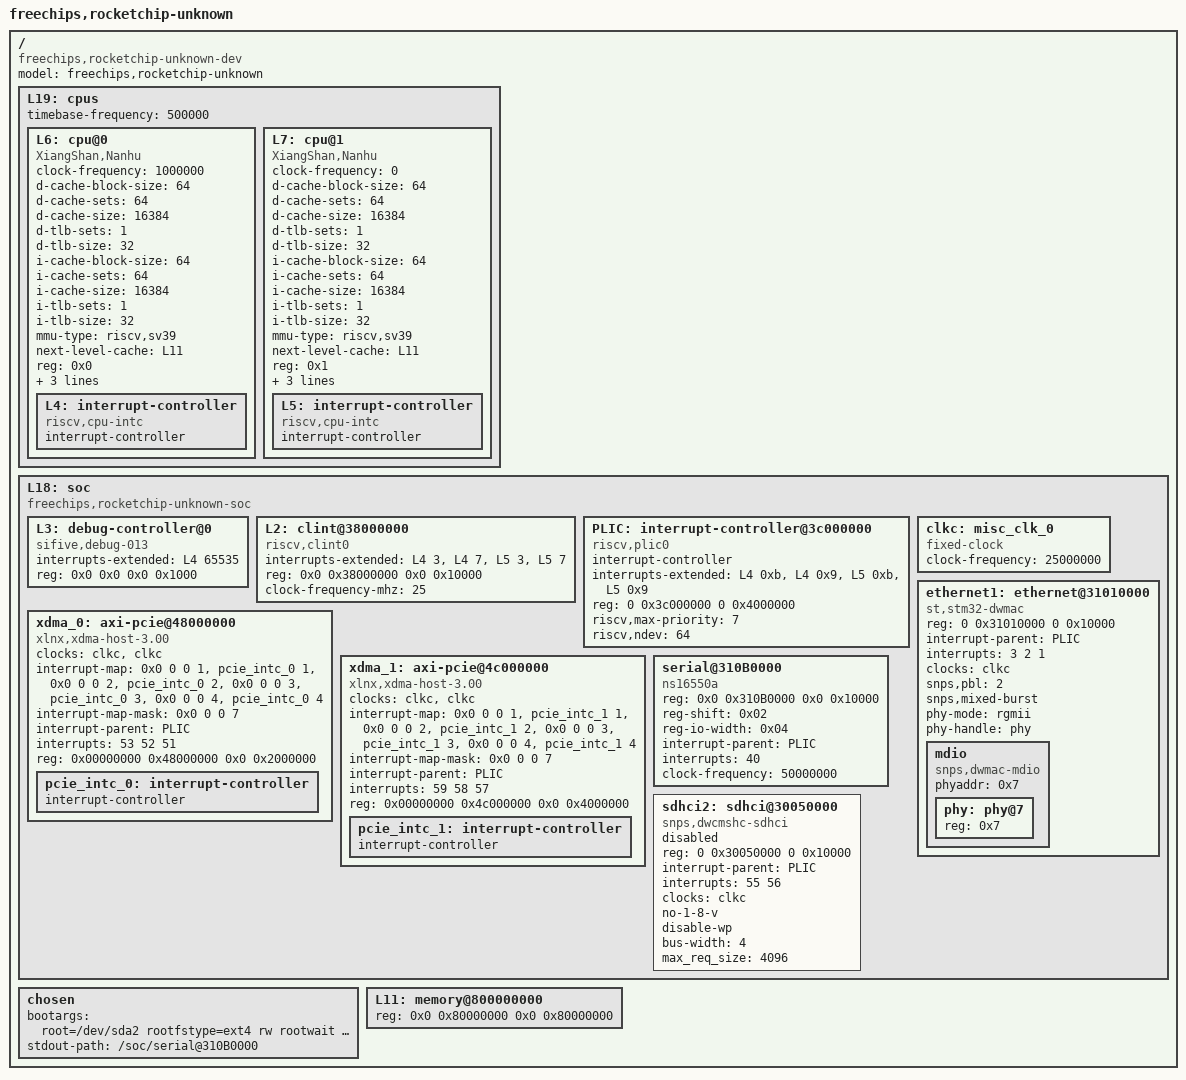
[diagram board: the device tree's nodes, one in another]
/dts-v1/;

/ {
	#address-cells = <2>;
	#size-cells = <2>;
	compatible = "freechips,rocketchip-unknown-dev";
	model = "freechips,rocketchip-unknown";
	L19: cpus {
		#address-cells = <1>;
		#size-cells = <0>;
    	timebase-frequency = <500000>;//500Khz
		L6: cpu@0 {
			clock-frequency = <1000000>;
			compatible = "XiangShan,Nanhu", "riscv";
			d-cache-block-size = <64>;
			d-cache-sets = <64>;
			d-cache-size = <16384>;
			d-tlb-sets = <1>;
			d-tlb-size = <32>;
			device_type = "cpu";
			i-cache-block-size = <64>;
			i-cache-sets = <64>;
			i-cache-size = <16384>;
			i-tlb-sets = <1>;
			i-tlb-size = <32>;
			mmu-type = "riscv,sv39";
			next-level-cache = <&L11>;
			reg = <0x0>;
			riscv,isa = "rv64imafdc";
			status = "okay";
			timebase-frequency = <500000>;//500Khz
			tlb-split;
			L4: interrupt-controller {
				#interrupt-cells = <1>;
				compatible = "riscv,cpu-intc";
				interrupt-controller;
			};
		};
        L7: cpu@1 {
			clock-frequency = <0>;
			compatible = "XiangShan,Nanhu", "riscv";
			d-cache-block-size = <64>;
			d-cache-sets = <64>;
			d-cache-size = <16384>;
			d-tlb-sets = <1>;
			d-tlb-size = <32>;
			device_type = "cpu";
			i-cache-block-size = <64>;
			i-cache-sets = <64>;
			i-cache-size = <16384>;
			i-tlb-sets = <1>;
			i-tlb-size = <32>;
			mmu-type = "riscv,sv39";
			next-level-cache = <&L11>;
			reg = <0x1>;
			riscv,isa = "rv64imafdc";
			status = "okay";
			timebase-frequency = <500000>;//500Khz
			tlb-split;
			L5: interrupt-controller {
				#interrupt-cells = <1>;
				compatible = "riscv,cpu-intc";
				interrupt-controller;
			};
		};

	};
	L18: soc {
		#address-cells = <2>;
		#size-cells = <2>;
		compatible = "freechips,rocketchip-unknown-soc", "simple-bus";
		ranges;
		L3: debug-controller@0 {
			compatible = "sifive,debug-013", "riscv,debug-013";
			interrupts-extended = <&L4 65535>;
			reg = <0x0 0x0 0x0 0x1000>;
			reg-names = "control";
		};

        L2: clint@38000000 {
            compatible = "riscv,clint0";
            interrupts-extended = <&L4 3 &L4 7 &L5 3 &L5 7>;
            reg = <0x0 0x38000000 0x0 0x10000>;
            reg-names = "control";
            clock-frequency-mhz = <25>;
        };

        PLIC: interrupt-controller@3c000000 {
            #interrupt-cells = <1>;
            compatible = "riscv,plic0";
            interrupt-controller;
            //interrupts-extended = <&L4 9 &L4 11 &L5 9 &L5 11>;
            interrupts-extended = <&L4 0xb &L4 0x9 &L5 0xb &L5 0x9>;
            //reg = <0 0xc000000 0 0x4000000>;
            reg = <0 0x3c000000 0 0x4000000>;
            reg-names = "control";
            riscv,max-priority = <7>;
            riscv,ndev = <64>;
        };

        clkc: misc_clk_0 {
            #clock-cells = <0>;
            clock-frequency = <25000000>;
            compatible = "fixed-clock";
        };

        ethernet1: ethernet@31010000 {
            compatible = "st,stm32-dwmac", "snps,dwmac-3.50a";
            reg = <0 0x31010000 0 0x10000>;
            reg-names = "stmmaceth";
            interrupt-parent = <&PLIC>;
            interrupts = <3 2 1>;
            interrupt-names = "eth_lpi", "macirq", "eth_wake_irq";
            clock-names = "stmmaceth";
            clocks = <&clkc>;
            //st,syscon = <&syscfg 0x4>;
            snps,pbl = <2>;
            snps,mixed-burst;
            phy-mode = "rgmii";
            // stmmac driver can not find phy if add this node
            //
            phy-handle = <&phy>;
                mdio {
                    #address-cells = <0x1>;
                    #size-cells = <0x0>;
                    phyaddr = <0x7>;
                    compatible = "snps,dwmac-mdio";
                    phy: phy@7 {
                    //phyaddr = <0x7>;
                    //compatible = "marvell,88e1116r";
                    //device_type = "ethernet-phy";
                    reg = <0x7>;
                };
            };
       };

       xdma_0: axi-pcie@48000000 {
            #address-cells = <3>;
            #interrupt-cells = <1>;
            #size-cells = <2>;
            clock-names = "sys_clk", "sys_clk_gt";
            clocks = <&clkc>, <&clkc>;
            compatible = "xlnx,xdma-host-3.00";
            device_type = "pci";
            interrupt-map =	<0x0 0 0 1 &pcie_intc_0 1>,
		   					<0x0 0 0 2 &pcie_intc_0 2>,
		   					<0x0 0 0 3 &pcie_intc_0 3>,
		   					<0x0 0 0 4 &pcie_intc_0 4>;
            interrupt-map-mask = <0x0 0 0 7>;
            interrupt-names = "misc", "msi0", "msi1";
            interrupt-parent = <&PLIC>;
            interrupts = <53 52 51>;
            //bus-range = <0x00 0xff>;
            ranges = <0x02000000 0x00000000 0x20000000 0x0 0x40000000 0x00000000 0x8000000>;
            reg = <0x00000000 0x48000000 0x0 0x2000000>;
            pcie_intc_0: interrupt-controller {
                #address-cells = <0>;
                #interrupt-cells = <1>;
                interrupt-controller ;
            };
        };

        xdma_1: axi-pcie@4c000000 {
            #address-cells = <3>;
            #interrupt-cells = <1>;
            #size-cells = <2>;
            clock-names = "sys_clk", "sys_clk_gt";
            clocks = <&clkc>, <&clkc>;
            compatible = "xlnx,xdma-host-3.00";
            device_type = "pci";
            interrupt-map =	<0x0 0 0 1 &pcie_intc_1 1>,
		   					<0x0 0 0 2 &pcie_intc_1 2>,
		   					<0x0 0 0 3 &pcie_intc_1 3>,
		   					<0x0 0 0 4 &pcie_intc_1 4>;
            interrupt-map-mask = <0x0 0 0 7>;
            interrupt-names = "misc", "msi0", "msi1";
            interrupt-parent = <&PLIC>;
            interrupts = <59 58 57>;
            //bus-range = <0x00 0xff>;
            ranges = <0x02000000 0x0 0x40000000 0x0 0x60000000 0x00000000 0x20000000>;
            reg = <0x00000000 0x4c000000 0x0 0x4000000>;
            pcie_intc_1: interrupt-controller {
                #address-cells = <0>;
                #interrupt-cells = <1>;
                interrupt-controller ;
            };
        };
                   
	    serial@310B0000 {
            compatible = "ns16550a";
            reg = <0x0 0x310B0000 0x0 0x10000>;
            reg-shift = <0x02>;
            reg-io-width = <0x04>;
            interrupt-parent = <&PLIC>;
            interrupts = <40>;
            clock-frequency = <50000000>;
            status = "okay";
	    };

	    sdhci2: sdhci@30050000 {
	    	compatible = "snps,dwcmshc-sdhci";
	    	reg = <0 0x30050000 0 0x10000>;
	    	interrupt-parent = <&PLIC>;
	    	interrupts = <55 56>;
	    	clocks = <&clkc>;
	    	clock-names = "core";
	    	//sd-uhs-sdr12;
	    	no-1-8-v;
	    	disable-wp;
	    	bus-width = <4>;
	    	max_req_size = <4096>;
	    	status = "disabled";
	    };
    };

    chosen {
         //bootargs = "root=/dev/nvme0n1p2 rootfstype=ext4 rw rootwait console=ttyS0,115200n8 earlycon noinitrd";
         bootargs = "root=/dev/sda2 rootfstype=ext4 rw rootwait console=ttyS0,115200n8 earlycon noinitrd";
         stdout-path = "/soc/serial@310B0000";
    };

    L11: memory@800000000 {
         device_type = "memory";
         reg = <0x0 0x80000000 0x0 0x80000000>;
    };
};

